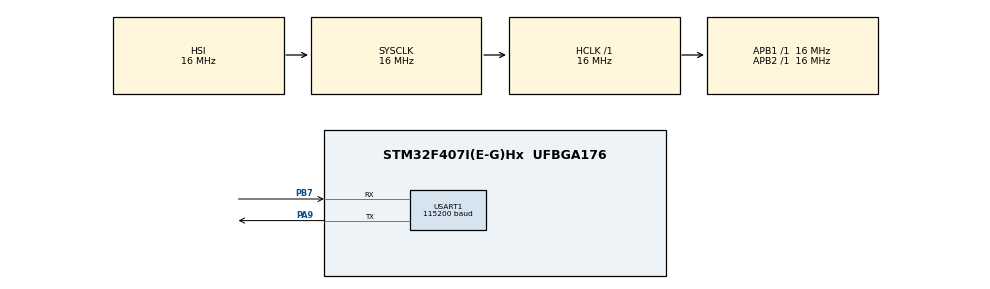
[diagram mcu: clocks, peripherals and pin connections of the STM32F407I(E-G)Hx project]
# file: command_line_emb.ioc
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Dma.Request0=USART1_RX
Dma.Request1=USART1_TX
Dma.USART1_RX.0.Direction=DMA_PERIPH_TO_MEMORY
Dma.USART1_RX.0.FIFOMode=DMA_FIFOMODE_DISABLE
Dma.USART1_RX.0.Instance=DMA2_Stream2
Dma.USART1_RX.0.MemDataAlignment=DMA_MDATAALIGN_BYTE
Dma.USART1_RX.0.MemInc=DMA_MINC_ENABLE
Dma.USART1_RX.0.Mode=DMA_NORMAL
Dma.USART1_RX.0.PeriphDataAlignment=DMA_PDATAALIGN_BYTE
Dma.USART1_RX.0.PeriphInc=DMA_PINC_DISABLE
Dma.USART1_RX.0.Priority=DMA_PRIORITY_LOW
Dma.USART1_TX.1.Direction=DMA_MEMORY_TO_PERIPH
Dma.USART1_TX.1.FIFOMode=DMA_FIFOMODE_DISABLE
Dma.USART1_TX.1.Instance=DMA2_Stream7
Dma.USART1_TX.1.MemDataAlignment=DMA_MDATAALIGN_BYTE
Dma.USART1_TX.1.MemInc=DMA_MINC_ENABLE
Dma.USART1_TX.1.Mode=DMA_NORMAL
Dma.USART1_TX.1.PeriphDataAlignment=DMA_PDATAALIGN_BYTE
Dma.USART1_TX.1.PeriphInc=DMA_PINC_DISABLE
Dma.USART1_TX.1.Priority=DMA_PRIORITY_LOW
Mcu.Family=STM32F4
Mcu.Name=STM32F407I(E-G)Hx
Mcu.Package=UFBGA176
NVIC.DMA2_Stream2_IRQn=true\:0\:0\:false\:false\:true\:false\:true\:true
NVIC.DMA2_Stream7_IRQn=true\:0\:0\:false\:false\:true\:false\:true\:true
NVIC.PriorityGroup=NVIC_PRIORITYGROUP_4
NVIC.USART1_IRQn=true\:0\:0\:false\:false\:false\:true\:true\:true
PA9.Mode=Asynchronous
PA9.Signal=USART1_TX
PB7.Mode=Asynchronous
PB7.Signal=USART1_RX
ProjectManager.HeapSize=0x200
ProjectManager.StackSize=0x400
ProjectManager.TargetToolchain=STM32CubeIDE
RCC.AHBFreq_Value=16000000
RCC.APB1Freq_Value=16000000
RCC.APB2Freq_Value=16000000
RCC.CortexFreq_Value=16000000
RCC.HSE_VALUE=25000000
RCC.HSI_VALUE=16000000
RCC.LSE_VALUE=32768
RCC.SYSCLKFreq_VALUE=16000000
RCC.VCOOutputFreq_Value=192000000
USART1.BaudRate=115200
USART1.VirtualMode=VM_ASYNC
board=custom

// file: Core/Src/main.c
/* USER CODE BEGIN Header */
/**
  ******************************************************************************
  * @file           : main.c
  * @brief          : Main program body
  ******************************************************************************
  * @attention
  *
  * Copyright (c) 2022 STMicroelectronics.
  * All rights reserved.
  *
  * This software is licensed under terms that can be found in the LICENSE file
  * in the root directory of this software component.
  * If no LICENSE file comes with this software, it is provided AS-IS.
  *
  ******************************************************************************
  */
/* USER CODE END Header */
#include "main.h"
#include "dma.h"
#include "usart.h"
#include "gpio.h"

void SystemClock_Config(void);

/* USER CODE BEGIN 0 */
command_line_buffer_t commandLineInputBuffer;
uint8_t rx_buffer[RX_BUFFER_LEN];
/* USER CODE END 0 */

int main(void)
{

  /* MCU Configuration--------------------------------------------------------*/

  /* Reset of all peripherals, Initializes the Flash interface and the Systick. */
  HAL_Init();

  /* Configure the system clock */
  SystemClock_Config();

  /* Initialize all configured peripherals */
  MX_GPIO_Init();
  MX_DMA_Init();
  MX_USART1_UART_Init();
  /* USER CODE BEGIN 2 */
  command_line_buffer_init(&commandLineInputBuffer, sizeof(char), 100);
  statement_t output_statement;
  statement_init(&output_statement, 100);
  /* USER CODE END 2 */

  /* Infinite loop */
  /* USER CODE BEGIN WHILE */
  while (1)
  {
//      if (get_output_statement(&commandLineInputBuffer, &output_statement) != command_line_no_error) {
//          HAL_Delay(10);
//          continue;
//      }
//      while (HAL_UART_Transmit_DMA(&huart1, (uint8_t *)output_statement.data, strlen(output_statement.data) +1) != HAL_OK) {
//          HAL_Delay(10);
//      }
      while (HAL_UART_Transmit_DMA(&huart1, (uint8_t *)"hello\n", strlen("hello\n")) != HAL_OK) {
          HAL_Delay(10);
      }
//      HAL_Delay(100);
    /* USER CODE END WHILE */

  }
}

void SystemClock_Config(void)
{
  RCC_OscInitTypeDef RCC_OscInitStruct = {0};
  RCC_ClkInitTypeDef RCC_ClkInitStruct = {0};

  /** Configure the main internal regulator output voltage
  */
  __HAL_RCC_PWR_CLK_ENABLE();
  __HAL_PWR_VOLTAGESCALING_CONFIG(PWR_REGULATOR_VOLTAGE_SCALE1);

  /** Initializes the RCC Oscillators according to the specified parameters
  * in the RCC_OscInitTypeDef structure.
  */
  RCC_OscInitStruct.OscillatorType = RCC_OSCILLATORTYPE_HSI;
  RCC_OscInitStruct.HSIState = RCC_HSI_ON;
  RCC_OscInitStruct.HSICalibrationValue = RCC_HSICALIBRATION_DEFAULT;
  RCC_OscInitStruct.PLL.PLLState = RCC_PLL_NONE;
  if (HAL_RCC_OscConfig(&RCC_OscInitStruct) != HAL_OK)
  {
    Error_Handler();
  }

  /** Initializes the CPU, AHB and APB buses clocks
  */
  RCC_ClkInitStruct.ClockType = RCC_CLOCKTYPE_HCLK|RCC_CLOCKTYPE_SYSCLK
                              |RCC_CLOCKTYPE_PCLK1|RCC_CLOCKTYPE_PCLK2;
  RCC_ClkInitStruct.SYSCLKSource = RCC_SYSCLKSOURCE_HSI;
  RCC_ClkInitStruct.AHBCLKDivider = RCC_SYSCLK_DIV1;
  RCC_ClkInitStruct.APB1CLKDivider = RCC_HCLK_DIV1;
  RCC_ClkInitStruct.APB2CLKDivider = RCC_HCLK_DIV1;

  if (HAL_RCC_ClockConfig(&RCC_ClkInitStruct, FLASH_LATENCY_0) != HAL_OK)
  {
    Error_Handler();
  }
}

void Error_Handler(void)
{
  __disable_irq();
  while (1)
  {
  }
}
